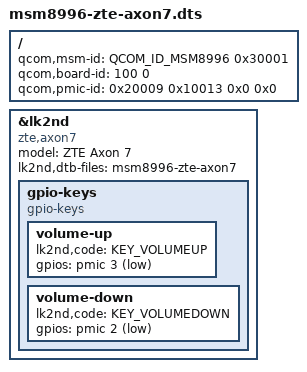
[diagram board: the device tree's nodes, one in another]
// SPDX-License-Identifier: BSD-3-Clause

#include <skeleton64.dtsi>
#include <lk2nd.dtsi>

/ {
	qcom,msm-id = <QCOM_ID_MSM8996 0x30001>;
	qcom,board-id = <100 0>;
	qcom,pmic-id = <0x20009 0x10013 0x0 0x0>;
};

&lk2nd {
	model = "ZTE Axon 7";
	compatible = "zte,axon7";
	lk2nd,dtb-files = "msm8996-zte-axon7";

	gpio-keys {
		compatible = "gpio-keys";

		volume-up {
			lk2nd,code = <KEY_VOLUMEUP>;
			gpios = <&pmic 3 (GPIO_ACTIVE_LOW | GPIO_PULL_UP)>;
		};

		volume-down {
			lk2nd,code = <KEY_VOLUMEDOWN>;
			gpios = <&pmic 2 (GPIO_ACTIVE_LOW | GPIO_PULL_UP)>;
		};
	};
};
